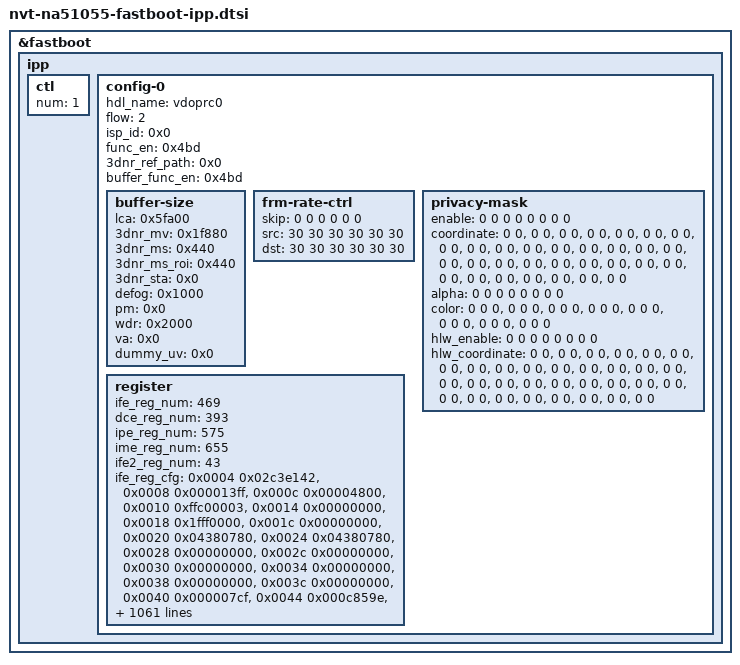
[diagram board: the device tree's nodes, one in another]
&fastboot {
	ipp {
		ctl {
			num = <1>;
		};
		config-0 {
			hdl_name = "vdoprc0";
			flow = <2>;
			isp_id = <0x0>;
			func_en = <0x4bd>;
			3dnr_ref_path = <0x0>;
			buffer_func_en = <0x4bd>;
			buffer-size {
				lca = <0x5fa00>;
				3dnr_mv = <0x1f880>;
				3dnr_ms = <0x440>;
				3dnr_ms_roi = <0x440>;
				3dnr_sta = <0x0>;
				defog = <0x1000>;
				pm = <0x0>;
				wdr = <0x2000>;
				va = <0x0>;
				dummy_uv = <0x0>;
			};
			frm-rate-ctrl {
				skip = <0 0 0 0 0 0>;
				src = <30 30 30 30 30 30>;
				dst = <30 30 30 30 30 30>;
			};
			privacy-mask {
				enable = <0 0 0 0 0 0 0 0>;
				coordinate =
					<0 0>, <0 0>, <0 0>, <0 0>,
					<0 0>, <0 0>, <0 0>, <0 0>,
					<0 0>, <0 0>, <0 0>, <0 0>,
					<0 0>, <0 0>, <0 0>, <0 0>,
					<0 0>, <0 0>, <0 0>, <0 0>,
					<0 0>, <0 0>, <0 0>, <0 0>,
					<0 0>, <0 0>, <0 0>, <0 0>,
					<0 0>, <0 0>, <0 0>, <0 0>;
				alpha = <0 0 0 0 0 0 0 0>;
				color =
					<0 0 0>,
					<0 0 0>,
					<0 0 0>,
					<0 0 0>,
					<0 0 0>,
					<0 0 0>,
					<0 0 0>,
					<0 0 0>;
				hlw_enable = <0 0 0 0 0 0 0 0>;
				hlw_coordinate =
					<0 0>, <0 0>, <0 0>, <0 0>,
					<0 0>, <0 0>, <0 0>, <0 0>,
					<0 0>, <0 0>, <0 0>, <0 0>,
					<0 0>, <0 0>, <0 0>, <0 0>,
					<0 0>, <0 0>, <0 0>, <0 0>,
					<0 0>, <0 0>, <0 0>, <0 0>,
					<0 0>, <0 0>, <0 0>, <0 0>,
					<0 0>, <0 0>, <0 0>, <0 0>;
			};
			register {
			  ife_reg_num = <469>;
			  dce_reg_num = <393>;
			  ipe_reg_num = <575>;
			  ime_reg_num = <655>;
			  ife2_reg_num = <43>;

			  ife_reg_cfg = 
			    <0x0004 0x02c3e142>,
			    <0x0008 0x000013ff>,
			    <0x000c 0x00004800>,
			    <0x0010 0xffc00003>,
			    <0x0014 0x00000000>,
			    <0x0018 0x1fff0000>,
			    <0x001c 0x00000000>,
			    <0x0020 0x04380780>,
			    <0x0024 0x04380780>,
			    <0x0028 0x00000000>,
			    <0x002c 0x00000000>,
			    <0x0030 0x00000000>,
			    <0x0034 0x00000000>,
			    <0x0038 0x00000000>,
			    <0x003c 0x00000000>,
			    <0x0040 0x000007cf>,
			    <0x0044 0x000c859e>,
			    <0x0048 0x00008b8c>,
			    <0x004c 0x00000000>,
			    <0x0050 0x00000000>,
			    <0x0054 0x00800000>,
			    <0x0058 0x00000000>,
			    <0x005c 0x00001000>,
			    <0x0060 0x00000000>,
			    <0x0064 0x00000000>,
			    <0x0068 0x00000000>,
			    <0x006c 0x00000000>,
			    <0x0070 0x000fff08>,
			    <0x0074 0x0110013e>,
			    <0x0078 0x02e50110>,
			    <0x007c 0x00000110>,
			    <0x0080 0x00800080>,
			    <0x0084 0x00800080>,
			    <0x0088 0x00000080>,
			    <0x008c 0x00800080>,
			    <0x0090 0x00800080>,
			    <0x0094 0x00000080>,
			    <0x0098 0x00000000>,
			    <0x009c 0x00000000>,
			    <0x00a0 0x00000000>,
			    <0x00a4 0x00000000>,
			    <0x00a8 0x00000000>,
			    <0x00ac 0x00000000>,
			    <0x00b0 0x00f000f0>,
			    <0x00b4 0x00f000f0>,
			    <0x00b8 0x000000f0>,
			    <0x00bc 0x00000000>,
			    <0x00c0 0x00000000>,
			    <0x00c4 0x00000000>,
			    <0x00c8 0x00000000>,
			    <0x00cc 0x00000000>,
			    <0x00d0 0x00000000>,
			    <0x00d4 0x00000000>,
			    <0x00d8 0x00000000>,
			    <0x00dc 0x00000000>,
			    <0x00e0 0x00000000>,
			    <0x00e4 0x00000000>,
			    <0x00e8 0x00000000>,
			    <0x00ec 0x00000000>,
			    <0x00f0 0x00000000>,
			    <0x00f4 0x00000000>,
			    <0x00f8 0x00000000>,
			    <0x00fc 0x00000000>,
			    <0x0100 0x00080000>,
			    <0x0104 0x00601600>,
			    <0x0108 0x0911171f>,
			    <0x010c 0x00000307>,
			    <0x0110 0x00000000>,
			    <0x0114 0x00010001>,
			    <0x0118 0x00020001>,
			    <0x011c 0x00000000>,
			    <0x0120 0x00000000>,
			    <0x0124 0x00010001>,
			    <0x0128 0x00020001>,
			    <0x012c 0x00000000>,
			    <0x0130 0x00000000>,
			    <0x0134 0x00010001>,
			    <0x0138 0x00020001>,
			    <0x013c 0x00000000>,
			    <0x0140 0x00000000>,
			    <0x0144 0x00010001>,
			    <0x0148 0x00020001>,
			    <0x014c 0x00000000>,
			    <0x0150 0x00000000>,
			    <0x0154 0x00020002>,
			    <0x0158 0x00040002>,
			    <0x015c 0x00000000>,
			    <0x0160 0x00000000>,
			    <0x0164 0x00020002>,
			    <0x0168 0x00040002>,
			    <0x016c 0x00000000>,
			    <0x0170 0x00000000>,
			    <0x0174 0x00020002>,
			    <0x0178 0x00040002>,
			    <0x017c 0x00000000>,
			    <0x0180 0x00000000>,
			    <0x0184 0x00020002>,
			    <0x0188 0x00040002>,
			    <0x018c 0x00000000>,
			    <0x0190 0x002c62c6>,
			    <0x0194 0x0040c40c>,
			    <0x0198 0x006af6af>,
			    <0x019c 0x0093d93d>,
			    <0x01a0 0x00f41f41>,
			    <0x01a4 0x00010000>,
			    <0x01a8 0x00010033>,
			    <0x01ac 0x86543210>,
			    <0x01b0 0x86543210>,
			    <0x01b4 0x00f00001>,
			    <0x01b8 0x008000a0>,
			    <0x01bc 0x000010ff>,
			    <0x01c0 0x00000000>,
			    <0x01c4 0x00010001>,
			    <0x01c8 0x00010001>,
			    <0x01cc 0x00020001>,
			    <0x01d0 0x00020002>,
			    <0x01d4 0x00020002>,
			    <0x01d8 0x00020002>,
			    <0x01dc 0x00030002>,
			    <0x01e0 0x00000003>,
			    <0x01e4 0x00000000>,
			    <0x01e8 0x00010001>,
			    <0x01ec 0x00010001>,
			    <0x01f0 0x00020001>,
			    <0x01f4 0x00020002>,
			    <0x01f8 0x00020002>,
			    <0x01fc 0x00020002>,
			    <0x0200 0x00030002>,
			    <0x0204 0x00000003>,
			    <0x0208 0x00000000>,
			    <0x020c 0x00010001>,
			    <0x0210 0x00010001>,
			    <0x0214 0x00020001>,
			    <0x0218 0x00020002>,
			    <0x021c 0x00020002>,
			    <0x0220 0x00020002>,
			    <0x0224 0x00030002>,
			    <0x0228 0x00000003>,
			    <0x022c 0x00000000>,
			    <0x0230 0x00010001>,
			    <0x0234 0x00010001>,
			    <0x0238 0x00020001>,
			    <0x023c 0x00020002>,
			    <0x0240 0x00020002>,
			    <0x0244 0x00020002>,
			    <0x0248 0x00030002>,
			    <0x024c 0x00000003>,
			    <0x0250 0x00000000>,
			    <0x0254 0x00020002>,
			    <0x0258 0x00020002>,
			    <0x025c 0x00040002>,
			    <0x0260 0x00040004>,
			    <0x0264 0x00040004>,
			    <0x0268 0x00040004>,
			    <0x026c 0x00060004>,
			    <0x0270 0x00000006>,
			    <0x0274 0x00000000>,
			    <0x0278 0x00020002>,
			    <0x027c 0x00020002>,
			    <0x0280 0x00040002>,
			    <0x0284 0x00040004>,
			    <0x0288 0x00040004>,
			    <0x028c 0x00040004>,
			    <0x0290 0x00060004>,
			    <0x0294 0x00000006>,
			    <0x0298 0x00000000>,
			    <0x029c 0x00020002>,
			    <0x02a0 0x00020002>,
			    <0x02a4 0x00040002>,
			    <0x02a8 0x00040004>,
			    <0x02ac 0x00040004>,
			    <0x02b0 0x00040004>,
			    <0x02b4 0x00060004>,
			    <0x02b8 0x00000006>,
			    <0x02bc 0x00000000>,
			    <0x02c0 0x00020002>,
			    <0x02c4 0x00020002>,
			    <0x02c8 0x00040002>,
			    <0x02cc 0x00040004>,
			    <0x02d0 0x00040004>,
			    <0x02d4 0x00040004>,
			    <0x02d8 0x00060004>,
			    <0x02dc 0x00000006>,
			    <0x02e0 0x021c03c0>,
			    <0x02e4 0x021c03c0>,
			    <0x02e8 0x021c03c0>,
			    <0x02ec 0x021c03c0>,
			    <0x02f0 0x003b73b8>,
			    <0x02f4 0xfffc0001>,
			    <0x02f8 0x00000000>,
			    <0x02fc 0x00000000>,
			    <0x0300 0x00000000>,
			    <0x0304 0x00000000>,
			    <0x0308 0x00000000>,
			    <0x030c 0x00000000>,
			    <0x0310 0x00000000>,
			    <0x0314 0x00000000>,
			    <0x0318 0x00000000>,
			    <0x031c 0x00000000>,
			    <0x0320 0x00000000>,
			    <0x0324 0x00000000>,
			    <0x0328 0x00000000>,
			    <0x032c 0x00000000>,
			    <0x0330 0x00000000>,
			    <0x0334 0x00000000>,
			    <0x0338 0x00000000>,
			    <0x033c 0x00000000>,
			    <0x0340 0x00000000>,
			    <0x0344 0x00000000>,
			    <0x0348 0x00000000>,
			    <0x034c 0x00000000>,
			    <0x0350 0x00000000>,
			    <0x0354 0x00000000>,
			    <0x0358 0x00000000>,
			    <0x035c 0x00000000>,
			    <0x0360 0x00000000>,
			    <0x0364 0x00000000>,
			    <0x0368 0x00000000>,
			    <0x036c 0x00000000>,
			    <0x0370 0x00000000>,
			    <0x0374 0x00000000>,
			    <0x0378 0x00000000>,
			    <0x037c 0x00000000>,
			    <0x0380 0x00000000>,
			    <0x0384 0x00000000>,
			    <0x0388 0x09060301>,
			    <0x038c 0x15120f0d>,
			    <0x0390 0x211e1b18>,
			    <0x0394 0x2d2a2724>,
			    <0x0398 0x00000030>,
			    <0x039c 0x1b181000>,
			    <0x03a0 0x1f1e1c1b>,
			    <0x03a4 0x1c1d1e1f>,
			    <0x03a8 0x0c1a1b1c>,
			    <0x03ac 0x00000004>,
			    <0x03b0 0x00000000>,
			    <0x03b4 0x00000000>,
			    <0x03b8 0x00000000>,
			    <0x03bc 0x00000000>,
			    <0x03c0 0x1f1f1f1f>,
			    <0x03c4 0x1e1e1f1f>,
			    <0x03c8 0x14181c1d>,
			    <0x03cc 0x080a0c10>,
			    <0x03d0 0x06060606>,
			    <0x03d4 0x05050505>,
			    <0x03d8 0x04040404>,
			    <0x03dc 0x20010203>,
			    <0x03e0 0x00000000>,
			    <0x03e4 0x00000000>,
			    <0x03e8 0x00000000>,
			    <0x03ec 0x00000000>,
			    <0x03f0 0x00000000>,
			    <0x03f4 0x00000000>,
			    <0x03f8 0x00000000>,
			    <0x03fc 0x00000000>,
			    <0x0400 0x80000000>,
			    <0x0404 0x00000000>,
			    <0x0408 0x00000000>,
			    <0x040c 0x01000000>,
			    <0x0410 0x00000000>,
			    <0x0414 0x00000000>,
			    <0x0418 0x00000000>,
			    <0x041c 0x01000000>,
			    <0x0420 0x00000000>,
			    <0x0424 0x00000000>,
			    <0x0428 0x00000000>,
			    <0x042c 0x00000000>,
			    <0x0430 0x00000000>,
			    <0x0434 0x00000000>,
			    <0x0438 0x00000000>,
			    <0x043c 0x00000000>,
			    <0x0440 0x00000000>,
			    <0x0444 0x00000000>,
			    <0x0448 0x00000000>,
			    <0x044c 0x00000000>,
			    <0x0450 0x00000000>,
			    <0x0454 0x00000000>,
			    <0x0458 0x00000000>,
			    <0x045c 0x00000000>,
			    <0x0460 0x00000000>,
			    <0x0464 0x00000000>,
			    <0x0468 0x00000000>,
			    <0x046c 0x00000000>,
			    <0x0470 0x00000000>,
			    <0x0474 0x00000000>,
			    <0x0478 0x00000000>,
			    <0x047c 0x00000000>,
			    <0x0480 0x00000000>,
			    <0x0484 0x00000000>,
			    <0x0488 0x00000000>,
			    <0x048c 0x00000000>,
			    <0x0490 0x00000000>,
			    <0x0494 0x00000000>,
			    <0x0498 0x00000000>,
			    <0x049c 0x00000000>,
			    <0x04a0 0x00000000>,
			    <0x04a4 0x00000000>,
			    <0x04a8 0x00000000>,
			    <0x04ac 0x00000000>,
			    <0x04b0 0x00000000>,
			    <0x04b4 0x00000000>,
			    <0x04b8 0x00000000>,
			    <0x04bc 0x00000000>,
			    <0x04c0 0x00000000>,
			    <0x04c4 0x00000000>,
			    <0x04c8 0x00000000>,
			    <0x04cc 0x00000000>,
			    <0x04d0 0x00000000>,
			    <0x04d4 0x00000000>,
			    <0x04d8 0x00000000>,
			    <0x04dc 0x00000000>,
			    <0x04e0 0x00000000>,
			    <0x04e4 0x00000000>,
			    <0x04e8 0x00000000>,
			    <0x04ec 0x00000000>,
			    <0x04f0 0x00000000>,
			    <0x04f4 0x00000000>,
			    <0x04f8 0x00000000>,
			    <0x04fc 0x00000000>,
			    <0x0500 0x00000000>,
			    <0x0504 0x00000000>,
			    <0x0508 0x00000000>,
			    <0x050c 0x00000000>,
			    <0x0510 0x00000000>,
			    <0x0514 0x00000000>,
			    <0x0518 0x00000000>,
			    <0x051c 0x00000000>,
			    <0x0520 0x00000000>,
			    <0x0524 0x00000000>,
			    <0x0528 0x00000000>,
			    <0x052c 0x00000000>,
			    <0x0530 0x00000000>,
			    <0x0534 0x00000000>,
			    <0x0538 0x00000000>,
			    <0x053c 0x00000000>,
			    <0x0540 0x00000000>,
			    <0x0544 0x00000000>,
			    <0x0548 0x00000000>,
			    <0x054c 0x00000000>,
			    <0x0550 0x00100110>,
			    <0x0554 0x0ea09ca0>,
			    <0x0558 0x80ea50ca>,
			    <0x055c 0x0c00a800>,
			    <0x0560 0x81007080>,
			    <0x0564 0x00000000>,
			    <0x0568 0x00000000>,
			    <0x056c 0x00000000>,
			    <0x0570 0x00000002>,
			    <0x0574 0x18a41040>,
			    <0x0578 0x10a63a0e>,
			    <0x057c 0x00000886>,
			    <0x0580 0x18a41040>,
			    <0x0584 0x10a63a0e>,
			    <0x0588 0x00000886>,
			    <0x058c 0x00000000>,
			    <0x0590 0xff100fff>,
			    <0x0594 0xff100fff>,
			    <0x0598 0x00000000>,
			    <0x059c 0x00000000>,
			    <0x05a0 0x00400010>,
			    <0x05a4 0x00000100>,
			    <0x05a8 0x00400000>,
			    <0x05ac 0x04000100>,
			    <0x05b0 0x00002222>,
			    <0x05b4 0x00000000>,
			    <0x05b8 0x00000000>,
			    <0x05bc 0x00000000>,
			    <0x05c0 0x00000000>,
			    <0x05c4 0x00000000>,
			    <0x05c8 0x00000000>,
			    <0x05cc 0x00000000>,
			    <0x05d0 0x00000000>,
			    <0x05d4 0x00000000>,
			    <0x05d8 0x00000000>,
			    <0x05dc 0x00000000>,
			    <0x05e0 0x00000000>,
			    <0x05e4 0x00000000>,
			    <0x05e8 0x00000000>,
			    <0x05ec 0x00000000>,
			    <0x05f0 0x00000000>,
			    <0x05f4 0x00000000>,
			    <0x05f8 0x00000000>,
			    <0x05fc 0x00000000>,
			    <0x0600 0x00000004>,
			    <0x0604 0xffffffff>,
			    <0x0608 0x80a0c0e0>,
			    <0x060c 0x10204060>,
			    <0x0610 0x00000000>,
			    <0x0614 0x00000000>,
			    <0x0618 0x06040200>,
			    <0x061c 0x0e0c0a08>,
			    <0x0620 0x16141210>,
			    <0x0624 0x1e1c1a18>,
			    <0x0628 0x26242220>,
			    <0x062c 0x2e2c2a28>,
			    <0x0630 0x36343230>,
			    <0x0634 0x3e3c3a38>,
			    <0x0638 0x55555555>,
			    <0x063c 0x55555555>,
			    <0x0640 0x03430000>,
			    <0x0644 0x060604e9>,
			    <0x0648 0x078b06de>,
			    <0x064c 0x0898081c>,
			    <0x0650 0x09670905>,
			    <0x0654 0x0a0e09be>,
			    <0x0658 0x0a9b0a57>,
			    <0x065c 0x0b140ad9>,
			    <0x0660 0x0b7f0b4b>,
			    <0x0664 0x0bde0bb0>,
			    <0x0668 0x0c340c0a>,
			    <0x066c 0x0c830c5c>,
			    <0x0670 0x0ccb0ca8>,
			    <0x0674 0x0d0d0ced>,
			    <0x0678 0x0d4b0d2d>,
			    <0x067c 0x0d850d69>,
			    <0x0680 0x0dbc0da1>,
			    <0x0684 0x0def0dd6>,
			    <0x0688 0x0e200e08>,
			    <0x068c 0x0e4e0e37>,
			    <0x0690 0x0e790e64>,
			    <0x0694 0x0ea30e8e>,
			    <0x0698 0x0ecb0eb7>,
			    <0x069c 0x0ef10ede>,
			    <0x06a0 0x0f150f03>,
			    <0x06a4 0x0f380f27>,
			    <0x06a8 0x0f5a0f49>,
			    <0x06ac 0x0f7a0f6a>,
			    <0x06b0 0x0f9a0f8a>,
			    <0x06b4 0x0fb80fa9>,
			    <0x06b8 0x0fd50fc7>,
			    <0x06bc 0x0ff20fe4>,
			    <0x06c0 0x00000fff>,
			    <0x06c4 0x00000000>,
			    <0x06c8 0x00000000>,
			    <0x06cc 0x00000000>,
			    <0x06d0 0x00000000>,
			    <0x06d4 0x00000000>,
			    <0x06d8 0x00000000>,
			    <0x06dc 0x00000000>,
			    <0x06e0 0x00000000>,
			    <0x06e4 0x00000000>,
			    <0x06e8 0x00000000>,
			    <0x06ec 0x00000000>,
			    <0x06f0 0x00000000>,
			    <0x06f4 0x00000000>,
			    <0x06f8 0x00000000>,
			    <0x06fc 0x00000000>,
			    <0x0700 0x00000011>,
			    <0x0704 0x0c080400>,
			    <0x0708 0x1c181410>,
			    <0x070c 0x0002aaaa>,
			    <0x0710 0x0002aaaa>,
			    <0x0714 0x00200000>,
			    <0x0718 0x00600040>,
			    <0x071c 0x00a00080>,
			    <0x0720 0x00e000c0>,
			    <0x0724 0x01440100>,
			    <0x0728 0x01e40190>,
			    <0x072c 0x02a40240>,
			    <0x0730 0x03840310>,
			    <0x0734 0x04840400>,
			    <0x0738 0x05a40510>,
			    <0x073c 0x06e40640>,
			    <0x0740 0x08440790>,
			    <0x0744 0x09c40900>,
			    <0x0748 0x0b640a90>,
			    <0x074c 0x0d240c40>,
			    <0x0750 0x0f040e10>,
			    <0x0754 0x00000fff>;

			  dce_reg_cfg = 
			    <0x0004 0x0000c47a>,
			    <0x0008 0x00001fdf>,
			    <0x000c 0x00000000>,
			    <0x0010 0x04380780>,
			    <0x0014 0x00000000>,
			    <0x0018 0x00000010>,
			    <0x001c 0x00400000>,
			    <0x0020 0x00400000>,
			    <0x0024 0x00000780>,
			    <0x0028 0x00400000>,
			    <0x002c 0x00000780>,
			    <0x0030 0x00400000>,
			    <0x0034 0x00000780>,
			    <0x0038 0x00400000>,
			    <0x003c 0x00000780>,
			    <0x0040 0x00000011>,
			    <0x0044 0x00000000>,
			    <0x0048 0x00000000>,
			    <0x004c 0x00000000>,
			    <0x0050 0x00000000>,
			    <0x0054 0x00000000>,
			    <0x0058 0x00000000>,
			    <0x005c 0x00000000>,
			    <0x0060 0x00003003>,
			    <0x0064 0x077f0000>,
			    <0x0068 0x077f0000>,
			    <0x006c 0x0000001e>,
			    <0x0070 0x00000000>,
			    <0x0074 0x00000000>,
			    <0x0078 0x00000000>,
			    <0x007c 0x00000000>,
			    <0x0080 0x00000000>,
			    <0x0084 0x00000000>,
			    <0x0088 0x00000000>,
			    <0x008c 0x00000780>,
			    <0x0090 0x00000000>,
			    <0x0094 0x00000000>,
			    <0x0098 0x00000000>,
			    <0x009c 0x00000000>,
			    <0x00a0 0x00000000>,
			    <0x00a4 0x00400000>,
			    <0x00a8 0x2c0003c0>,
			    <0x00ac 0x000a0028>,
			    <0x00b0 0x80000000>,
			    <0x00b4 0x00000000>,
			    <0x00b8 0xf8888888>,
			    <0x00bc 0x485f7880>,
			    <0x00c0 0x2428303a>,
			    <0x00c4 0x20202020>,
			    <0x00c8 0x20202020>,
			    <0x00cc 0x00a00020>,
			    <0x00d0 0x00014008>,
			    <0x00d4 0x122347ff>,
			    <0x00d8 0x00000111>,
			    <0x00dc 0x00000000>,
			    <0x00e0 0x40081007>,
			    <0x00e4 0x00408003>,
			    <0x00e8 0x00cc00cc>,
			    <0x00ec 0xa80080e6>,
			    <0x00f0 0x00800080>,
			    <0x00f4 0x00010080>,
			    <0x00f8 0x00000100>,
			    <0x00fc 0xffffe0c0>,
			    <0x0100 0x00000000>,
			    <0x0104 0x00000000>,
			    <0x0108 0x00000000>,
			    <0x010c 0x00000000>,
			    <0x0110 0x00000000>,
			    <0x0114 0x00000000>,
			    <0x0118 0x00000000>,
			    <0x011c 0x00000000>,
			    <0x0120 0x0000023f>,
			    <0x0124 0x00400000>,
			    <0x0128 0x00000080>,
			    <0x012c 0x1a734f40>,
			    <0x0130 0x00000100>,
			    <0x0134 0x04080422>,
			    <0x0138 0x0f79cc3b>,
			    <0x013c 0x0fde1c3b>,
			    <0x0140 0x00000000>,
			    <0x0144 0xffffffff>,
			    <0x0148 0xffffffff>,
			    <0x014c 0xffffffff>,
			    <0x0150 0xffffffff>,
			    <0x0154 0x200000ff>,
			    <0x0158 0x00000054>,
			    <0x015c 0x1565193c>,
			    <0x0160 0x160c160c>,
			    <0x0164 0x55050003>,
			    <0x0168 0x00000000>,
			    <0x016c 0x00000000>,
			    <0x0170 0x00000000>,
			    <0x0174 0x00000000>,
			    <0x0178 0x00000000>,
			    <0x017c 0x00000000>,
			    <0x0180 0x00000000>,
			    <0x0184 0x00000000>,
			    <0x0188 0x00000000>,
			    <0x018c 0x00000000>,
			    <0x0190 0x00000000>,
			    <0x0194 0x00000000>,
			    <0x0198 0x00000000>,
			    <0x019c 0x00000000>,
			    <0x01a0 0x00000000>,
			    <0x01a4 0x00000000>,
			    <0x01a8 0x00000000>,
			    <0x01ac 0x00000000>,
			    <0x01b0 0x00000000>,
			    <0x01b4 0x00000000>,
			    <0x01b8 0x00000000>,
			    <0x01bc 0x00000000>,
			    <0x01c0 0x00000000>,
			    <0x01c4 0x00000000>,
			    <0x01c8 0x00000000>,
			    <0x01cc 0x00000000>,
			    <0x01d0 0x00000000>,
			    <0x01d4 0x00000000>,
			    <0x01d8 0x00000000>,
			    <0x01dc 0x00000000>,
			    <0x01e0 0x00000000>,
			    <0x01e4 0x00000000>,
			    <0x01e8 0x00000000>,
			    <0x01ec 0x00000000>,
			    <0x01f0 0x00000000>,
			    <0x01f4 0x00000000>,
			    <0x01f8 0x00000000>,
			    <0x01fc 0x00000000>,
			    <0x0200 0x00000000>,
			    <0x0204 0x00000000>,
			    <0x0208 0x00000000>,
			    <0x020c 0x00000000>,
			    <0x0210 0x00000000>,
			    <0x0214 0x18100800>,
			    <0x0218 0x2624201c>,
			    <0x021c 0x2b2a2928>,
			    <0x0220 0x2f2e2d2c>,
			    <0x0224 0x33323130>,
			    <0x0228 0x37363534>,
			    <0x022c 0x3b3a3938>,
			    <0x0230 0x3f3e3d3c>,
			    <0x0234 0x00005abf>,
			    <0x0238 0x00000000>,
			    <0x023c 0x0ff70fff>,
			    <0x0240 0x0fa10fd8>,
			    <0x0244 0x0ef10f54>,
			    <0x0248 0x0df70e7b>,
			    <0x024c 0x0cd10d68>,
			    <0x0250 0x0b9d0c37>,
			    <0x0254 0x0a700b04>,
			    <0x0258 0x095909e1>,
			    <0x025c 0x085f08d8>,
			    <0x0260 0x078407ee>,
			    <0x0264 0x06c70722>,
			    <0x0268 0x06240673>,
			    <0x026c 0x055c05dc>,
			    <0x0270 0x049004ee>,
			    <0x0274 0x03f9043f>,
			    <0x0278 0x038803bd>,
			    <0x027c 0x0332035b>,
			    <0x0280 0x02f0030f>,
			    <0x0284 0x02a602d4>,
			    <0x0288 0x02620280>,
			    <0x028c 0x02230249>,
			    <0x0290 0x01f30208>,
			    <0x0294 0x01d801e4>,
			    <0x0298 0x01c801cf>,
			    <0x029c 0x01bd01c2>,
			    <0x02a0 0x01b501b9>,
			    <0x02a4 0x01b001b2>,
			    <0x02a8 0x01ac01ae>,
			    <0x02ac 0x01a901aa>,
			    <0x02b0 0x01a601a7>,
			    <0x02b4 0x01a401a5>,
			    <0x02b8 0x01a301a4>,
			    <0x02bc 0x000001a2>,
			    <0x02c0 0x0000808c>,
			    <0x02c4 0xffff0000>,
			    <0x02c8 0x00000000>,
			    <0x02cc 0x00000000>,
			    <0x02d0 0x00000000>,
			    <0x02d4 0x09750679>,
			    <0x02d8 0x17210427>,
			    <0x02dc 0x94f26029>,
			    <0x02e0 0x92cc95d2>,
			    <0x02e4 0xa78ca2b4>,
			    <0x02e8 0xddbeb943>,
			    <0x02ec 0xffffffff>,
			    <0x02f0 0xffffffff>,
			    <0x02f4 0xffffffff>,
			    <0x02f8 0xc2eeffff>,
			    <0x02fc 0x822fa1ed>,
			    <0x0300 0x678a6dc1>,
			    <0x0304 0x72b16c5f>,
			    <0x0308 0x831d7bd1>,
			    <0x030c 0x98db8df1>,
			    <0x0310 0x840792f6>,
			    <0x0314 0x717c7637>,
			    <0x0318 0x5a01696c>,
			    <0x031c 0x4c105384>,
			    <0x0320 0x3ba741d7>,
			    <0x0324 0x34e237cf>,
			    <0x0328 0x30223287>,
			    <0x032c 0x2a4d2d8d>,
			    <0x0330 0x27ae2917>,
			    <0x0334 0x24aa2697>,
			    <0x0338 0x2288234c>,
			    <0x033c 0x1fbd204e>,
			    <0x0340 0x1ee01fdd>,
			    <0x0344 0x1ca51db7>,
			    <0x0348 0x1b071b5c>,
			    <0x034c 0x1a121a4e>,
			    <0x0350 0x1e9f1af9>,
			    <0x0354 0x1f33200d>,
			    <0x0358 0x22a020d2>,
			    <0x035c 0x1dc32041>,
			    <0x0360 0x1a491b55>,
			    <0x0364 0x1b691a98>,
			    <0x0368 0x1c3e1b30>,
			    <0x036c 0x1fc21d73>,
			    <0x0370 0x1fcf2073>,
			    <0x0374 0x1a421e11>,
			    <0x0378 0x1da01a78>,
			    <0x037c 0x1c971d84>,
			    <0x0380 0x11251975>,
			    <0x0384 0x0c430d07>,
			    <0x0388 0x0bad0bac>,
			    <0x038c 0x0b790b06>,
			    <0x0390 0x08660ac7>,
			    <0x0394 0x05860604>,
			    <0x0398 0x05220527>,
			    <0x039c 0x04ba04ad>,
			    <0x03a0 0x03310429>,
			    <0x03a4 0x015e0208>,
			    <0x03a8 0x00f20111>,
			    <0x03ac 0x00d400d1>,
			    <0x03b0 0x00fa00e9>,
			    <0x03b4 0x00a200b3>,
			    <0x03b8 0x008f00b3>,
			    <0x03bc 0x00810078>,
			    <0x03c0 0x004d0060>,
			    <0x03c4 0x004c005d>,
			    <0x03c8 0x00620053>,
			    <0x03cc 0x005f0051>,
			    <0x03d0 0x037f0074>,
			    <0x03d4 0x00000000>,
			    <0x03d8 0x00000000>,
			    <0x03dc 0x00000000>,
			    <0x03e0 0x00000000>,
			    <0x03e4 0x00000000>,
			    <0x03e8 0x00000000>,
			    <0x03ec 0x00000000>,
			    <0x03f0 0x00000000>,
			    <0x03f4 0x00000000>,
			    <0x03f8 0x00000000>,
			    <0x03fc 0x00000000>,
			    <0x0400 0x00000002>,
			    <0x0404 0x021c03c0>,
			    <0x0408 0x00ffffff>,
			    <0x040c 0x12661599>,
			    <0x0410 0x00000400>,
			    <0x0414 0x3fffffff>,
			    <0x0418 0x10001000>,
			    <0x041c 0x00001000>,
			    <0x0420 0x00000000>,
			    <0x0424 0x00000000>,
			    <0x0428 0x00000000>,
			    <0x042c 0x00000000>,
			    <0x0430 0x00000000>,
			    <0x0434 0x00000000>,
			    <0x0438 0x00000000>,
			    <0x043c 0x00000000>,
			    <0x0440 0xffffffff>,
			    <0x0444 0xffffffff>,
			    <0x0448 0xffffffff>,
			    <0x044c 0xffffffff>,
			    <0x0450 0xffffffff>,
			    <0x0454 0xffffffff>,
			    <0x0458 0xffffffff>,
			    <0x045c 0xffffffff>,
			    <0x0460 0xffffffff>,
			    <0x0464 0xffffffff>,
			    <0x0468 0xffffffff>,
			    <0x046c 0xffffffff>,
			    <0x0470 0xffffffff>,
			    <0x0474 0xffffffff>,
			    <0x0478 0xffffffff>,
			    <0x047c 0xffffffff>,
			    <0x0480 0xffffffff>,
			    <0x0484 0xffffffff>,
			    <0x0488 0xffffffff>,
			    <0x048c 0xffffffff>,
			    <0x0490 0xffffffff>,
			    <0x0494 0xffffffff>,
			    <0x0498 0xffffffff>,
			    <0x049c 0xffffffff>,
			    <0x04a0 0xffffffff>,
			    <0x04a4 0xffffffff>,
			    <0x04a8 0xffffffff>,
			    <0x04ac 0xffffffff>,
			    <0x04b0 0xffffffff>,
			    <0x04b4 0xffffffff>,
			    <0x04b8 0xffffffff>,
			    <0x04bc 0xffffffff>,
			    <0x04c0 0x0000ffff>,
			    <0x04c4 0x00000000>,
			    <0x04c8 0x00000000>,
			    <0x04cc 0x00000000>,
			    <0x04d0 0x00000000>,
			    <0x04d4 0x00000000>,
			    <0x04d8 0x00000000>,
			    <0x04dc 0x00000000>,
			    <0x04e0 0x00000000>,
			    <0x04e4 0x00000000>,
			    <0x04e8 0x00000000>,
			    <0x04ec 0x00000000>,
			    <0x04f0 0x00000000>,
			    <0x04f4 0x00000000>,
			    <0x04f8 0x00000000>,
			    <0x04fc 0x00000000>,
			    <0x0500 0x00000000>,
			    <0x0504 0x00000000>,
			    <0x0508 0x00000000>,
			    <0x050c 0x00000000>,
			    <0x0510 0x00000000>,
			    <0x0514 0x00000000>,
			    <0x0518 0x00000000>,
			    <0x051c 0x00000000>,
			    <0x0520 0x00000000>,
			    <0x0524 0x00000000>,
			    <0x0528 0x00000000>,
			    <0x052c 0x00000000>,
			    <0x0530 0x00000000>,
			    <0x0534 0x00000000>,
			    <0x0538 0x00000000>,
			    <0x053c 0x00000000>,
			    <0x0540 0x00000000>,
			    <0x0544 0x00000000>,
			    <0x0548 0x00000000>,
			    <0x054c 0x00000000>,
			    <0x0550 0x00000000>,
			    <0x0554 0x00000000>,
			    <0x0558 0x00000000>,
			    <0x055c 0x00000000>,
			    <0x0560 0x00000000>,
			    <0x0564 0x00000000>,
			    <0x0568 0x00000000>,
			    <0x056c 0x00000000>,
			    <0x0570 0x00000000>,
			    <0x0574 0x00000000>,
			    <0x0578 0x00000000>,
			    <0x057c 0x00000000>,
			    <0x0580 0x00000000>,
			    <0x0584 0x00000000>,
			    <0x0588 0x00000000>,
			    <0x058c 0x00000000>,
			    <0x0590 0x00000000>,
			    <0x0594 0x00000000>,
			    <0x0598 0x00000000>,
			    <0x059c 0x00000000>,
			    <0x05a0 0x00000000>,
			    <0x05a4 0x00000000>,
			    <0x05a8 0x00000000>,
			    <0x05ac 0x00000000>,
			    <0x05b0 0x00000000>,
			    <0x05b4 0x00000000>,
			    <0x05b8 0x00000000>,
			    <0x05bc 0x00000000>,
			    <0x05c0 0x00000000>,
			    <0x05c4 0x00000000>,
			    <0x05c8 0x00000000>,
			    <0x05cc 0x00000000>,
			    <0x05d0 0x00000000>,
			    <0x05d4 0x00000000>,
			    <0x05d8 0x00000000>,
			    <0x05dc 0x00000000>,
			    <0x05e0 0x00000000>,
			    <0x05e4 0x00000000>,
			    <0x05e8 0x00000000>,
			    <0x05ec 0x00000000>,
			    <0x05f0 0x00400000>,
			    <0x05f4 0x00000000>,
			    <0x05f8 0x00000000>,
			    <0x05fc 0x00000000>,
			    <0x0600 0x00000000>,
			    <0x0604 0x00000000>,
			    <0x0608 0x00000000>,
			    <0x060c 0x00000000>,
			    <0x0610 0x20191230>,
			    <0x0614 0x00000000>,
			    <0x0618 0x00000000>,
			    <0x061c 0x00000000>,
			    <0x0620 0x00000000>,
			    <0x0624 0x00000000>;

			  ipe_reg_cfg = 
			    <0x0004 0x00000006>,
			    <0x0008 0x00017edb>,
			    <0x000c 0x00000018>,
			    <0x0010 0x00000000>,
			    <0x0014 0x001e0000>,
			    <0x0018 0x00000438>,
			    <0x001c 0x00000000>,
			    <0x0020 0x00000000>,
			    <0x0024 0x00000000>,
			    <0x0028 0x00000000>,
			    <0x002c 0x1a66e1e4>,
			    <0x0030 0x00000000>,
			    <0x0034 0x00000000>,
			    <0x0038 0x00800000>,
			    <0x003c 0x00800000>,
			    <0x0040 0x00000000>,
			    <0x0044 0x00000000>,
			    <0x0048 0x10000000>,
			    <0x004c 0x00000000>,
			    <0x0050 0x00001ffe>,
			    <0x0054 0x00000000>,
			    <0x0058 0xff040001>,
			    <0x005c 0x00000000>,
			    <0x0060 0x00000000>,
			    <0x0064 0x00000000>,
			    <0x0068 0x00000000>,
			    <0x006c 0x00000000>,
			    <0x0070 0x017c05a3>,
			    <0x0074 0x3e2ec02a>,
			    <0x0078 0x00a013dd>,
			    <0x007c 0x0010100a>,
			    <0x0080 0x00181818>,
			    <0x0084 0x00000333>,
			    <0x0088 0x00010004>,
			    <0x008c 0x00008888>,
			    <0x0090 0x88881000>,
			    <0x0094 0x0006e041>,
			    <0x0098 0xffc6e032>,
			    <0x009c 0x0111016c>,
			    <0x00a0 0x00800801>,
			    <0x00a4 0xffff14b4>,
			    <0x00a8 0x00010000>,
			    <0x00ac 0x01000100>,
			    <0x00b0 0x00600060>,
			    <0x00b4 0x05080000>,
			    <0x00b8 0x40352d20>,
			    <0x00bc 0x40404040>,
			    <0x00c0 0x40404040>,
			    <0x00c4 0x262c3440>,
			    <0x00c8 0x15014000>,
			    <0x00cc 0x40201000>,
			    <0x00d0 0xfff0b480>,
			    <0x00d4 0xd6e2f0ff>,
			    <0x00d8 0xb8bec4cc>,
			    <0x00dc 0x02ccc3ff>,
			    <0x00e0 0x40400001>,
			    <0x00e4 0x00000000>,
			    <0x00e8 0x00004040>,
			    <0x00ec 0x00000000>,
			    <0x00f0 0x41000804>,
			    <0x00f4 0x41000804>,
			    <0x00f8 0x41000804>,
			    <0x00fc 0x00000000>,
			    <0x0100 0x01200001>,
			    <0x0104 0x0fc90018>,
			    <0x0108 0x01bb0f78>,
			    <0x010c 0x0ffd0fcd>,
			    <0x0110 0x01bb0f48>,
			    <0x0114 0x00104080>,
			    <0x0118 0x00000000>,
			    <0x011c 0x00000000>,
			    <0x0120 0x00000000>,
			    <0x0124 0x050a0f14>,
			    <0x0128 0x00000000>,
			    <0x012c 0x00000000>,
			    <0x0130 0x0f0a0500>,
			    <0x0134 0x00000000>,
			    <0x0138 0x10752c4d>,
			    <0x013c 0x120357d5>,
			    <0x0140 0x07af2a80>,
			    <0x0144 0x00000000>,
			    <0x0148 0x282000f4>,
			    <0x014c 0x80808080>,
			    <0x0150 0x80808080>,
			    <0x0154 0x80808080>,
			    <0x0158 0x80808080>,
			    <0x015c 0x80808080>,
			    <0x0160 0x80808080>,
			    <0x0164 0x00000000>,
			    <0x0168 0x00000000>,
			    <0x016c 0x00000000>,
			    <0x0170 0x00000000>,
			    <0x0174 0x00000000>,
			    <0x0178 0x00000000>,
			    <0x017c 0x00000000>,
			    <0x0180 0x00000000>,
			    <0x0184 0x00000000>,
			    <0x0188 0x00000000>,
			    <0x018c 0x00000000>,
			    <0x0190 0x00000000>,
			    <0x0194 0x80808080>,
			    <0x0198 0x80808080>,
			    <0x019c 0x80808080>,
			    <0x01a0 0x80808080>,
			    <0x01a4 0x80808080>,
			    <0x01a8 0x80808080>,
			    <0x01ac 0x00820820>,
			    <0x01b0 0x00820820>,
			    <0x01b4 0x00000000>,
			    <0x01b8 0x0000f03c>,
			    <0x01bc 0x0000008c>,
			    <0x01c0 0x00000000>,
			    <0x01c4 0x00000000>,
			    <0x01c8 0x00ffffff>,
			    <0x01cc 0x008c8080>,
			    <0x01d0 0x80808080>,
			    <0x01d4 0x00000000>,
			    <0x01d8 0x00000000>,
			    <0x01dc 0x08020080>,
			    <0x01e0 0x08020080>,
			    <0x01e4 0x08020080>,
			    <0x01e8 0x08020080>,
			    <0x01ec 0x08020080>,
			    <0x01f0 0x00020080>,
			    <0x01f4 0x00000000>,
			    <0x01f8 0x00000000>,
			    <0x01fc 0x00000000>,
			    <0x0200 0x00000000>,
			    <0x0204 0x00000000>,
			    <0x0208 0x00000000>,
			    <0x020c 0x00000000>,
			    <0x0210 0x00000000>,
			    <0x0214 0x00000000>,
			    <0x0218 0x00000000>,
			    <0x021c 0x00000000>,
			    <0x0220 0x00000000>,
			    <0x0224 0x00000000>,
			    <0x0228 0x00000000>,
			    <0x022c 0x00000000>,
			    <0x0230 0x00000000>,
			    <0x0234 0x00000000>,
			    <0x0238 0x00000000>,
			    <0x023c 0x00000000>,
			    <0x0240 0x00000000>,
			    <0x0244 0x00000000>,
			    <0x0248 0x00000000>,
			    <0x024c 0x00000000>,
			    <0x0250 0x00000000>,
			    <0x0254 0x00000000>,
			    <0x0258 0x00000000>,
			    <0x025c 0x00000000>,
			    <0x0260 0x00000000>,
			    <0x0264 0x00000000>,
			    <0x0268 0x00000000>,
			    <0x026c 0x00000000>,
			    <0x0270 0x00000000>,
			    <0x0274 0x00000000>,
			    <0x0278 0x00000000>,
			    <0x027c 0x00000000>,
			    <0x0280 0x00000000>,
			    <0x0284 0x00000000>,
			    <0x0288 0x00000000>,
			    <0x028c 0x00000000>,
			    <0x0290 0x00000000>,
			    <0x0294 0x00000000>,
			    <0x0298 0x00000000>,
			    <0x029c 0x00000000>,
			    <0x02a0 0x00000000>,
			    <0x02a4 0x00000000>,
			    <0x02a8 0x00000000>,
			    <0x02ac 0x00000000>,
			    <0x02b0 0x00000000>,
			    <0x02b4 0x00000000>,
			    <0x02b8 0x00000000>,
			    <0x02bc 0x00000000>,
			    <0x02c0 0x0000010f>,
			    <0x02c4 0x1a731f40>,
			    <0x02c8 0x00000040>,
			    <0x02cc 0x1a730f40>,
			    <0x02d0 0x00000040>,
			    <0x02d4 0x01e50200>,
			    <0x02d8 0x1ffbb877>,
			    <0x02dc 0x21b80077>,
			    <0x02e0 0x00000000>,
			    <0x02e4 0x00000000>,
			    <0x02e8 0x00000000>,
			    <0x02ec 0x00000000>,
			    <0x02f0 0x00000054>,
			    <0x02f4 0x00000000>,
			    <0x02f8 0x00000000>,
			    <0x02fc 0x00000000>,
			    <0x0300 0x00000000>,
			    <0x0304 0x00000000>,
			    <0x0308 0x00000000>,
			    <0x030c 0x00000000>,
			    <0x0310 0x00000000>,
			    <0x0314 0x00000000>,
			    <0x0318 0x00000000>,
			    <0x031c 0x00000000>,
			    <0x0320 0x00000000>,
			    <0x0324 0x00000000>,
			    <0x0328 0x00000000>,
			    <0x032c 0x00000000>,
			    <0x0330 0x00000000>,
			    <0x0334 0x00000000>,
			    <0x0338 0x00000000>,
			    <0x033c 0x00000818>,
			    <0x0340 0x00000000>,
			    <0x0344 0x00000000>,
			    <0x0348 0x00000000>,
			    <0x034c 0x00000000>,
			    <0x0350 0x00000000>,
			    <0x0354 0x00000000>,
			    <0x0358 0x0ff200ff>,
			    <0x035c 0x000000ff>,
			    <0x0360 0x00000000>,
			    <0x0364 0x00000000>,
			    <0x0368 0x00000000>,
			    <0x036c 0x00000000>,
			    <0x0370 0x00000000>,
			    <0x0374 0x00000000>,
			    <0x0378 0x00000000>,
			    <0x037c 0x00000000>,
			    <0x0380 0x00000000>,
			    <0x0384 0x00800000>,
			    <0x0388 0x54545454>,
			    <0x038c 0x54545454>,
			    <0x0390 0x00000054>,
			    <0x0394 0x00000000>,
			    <0x0398 0x00000000>,
			    <0x039c 0x00000000>,
			    <0x03a0 0x00e00004>,
			    <0x03a4 0x4000d200>,
			    <0x03a8 0x00000000>,
			    <0x03ac 0x00000000>,
			    <0x03b0 0x00000000>,
			    <0x03b4 0x00000000>,
			    <0x03b8 0x00000000>,
			    <0x03bc 0x00000000>,
			    <0x03c0 0x00000000>,
			    <0x03c4 0x00000000>,
			    <0x03c8 0x00000000>,
			    <0x03cc 0x00000000>,
			    <0x03d0 0x00000000>,
			    <0x03d4 0x00000000>,
			    <0x03d8 0x00000000>,
			    <0x03dc 0x00000000>,
			    <0x03e0 0x00000000>,
			    <0x03e4 0x00000000>,
			    <0x03e8 0x00000000>,
			    <0x03ec 0x00000000>,
			    <0x03f0 0x00000000>,
			    <0x03f4 0x00000000>,
			    <0x03f8 0x00000000>,
			    <0x03fc 0x00000000>,
			    <0x0400 0x33acd730>,
			    <0x0404 0x33acd730>,
			    <0x0408 0x33acd730>,
			    <0x040c 0x33acd730>,
			    <0x0410 0x33acd730>,
			    <0x0414 0x33acd730>,
			    <0x0418 0x0c62a48b>,
			    <0x041c 0x34dd2343>,
			    <0x0420 0x34dd2343>,
			    <0x0424 0x34dd2343>,
			    <0x0428 0x34dd2343>,
			    <0x042c 0x34dd2343>,
			    <0x0430 0x34dd2343>,
			    <0x0434 0x111404f1>,
			    <0x0438 0x343cfb3a>,
			    <0x043c 0x343cfb3a>,
			    <0x0440 0x343cfb3a>,
			    <0x0444 0x343cfb3a>,
			    <0x0448 0x343cfb3a>,
			    <0x044c 0x2e8b8edd>,
			    <0x0450 0x0f1384c6>,
			    <0x0454 0x326c871d>,
			    <0x0458 0x326c871d>,
			    <0x045c 0x326c871d>,
			    <0x0460 0x326c871d>,
			    <0x0464 0x326c871d>,
			    <0x0468 0x3fffeff7>,
			    <0x046c 0x2ffbeaf4>,
			    <0x0470 0x2ffbeaf4>,
			    <0x0474 0x2ffbeaf4>,
			    <0x0478 0x2ffbeaf4>,
			    <0x047c 0x2ffbeaf4>,
			    <0x0480 0x2ffbeaf4>,
			    <0x0484 0x0f1384c6>,
			    <0x0488 0x2c5afeb9>,
			    <0x048c 0x2c5afeb9>,
			    <0x0490 0x2c5afeb9>,
			    <0x0494 0x2c5afeb9>,
			    <0x0498 0x2c5afeb9>,
			    <0x049c 0x2c5afeb9>,
			    <0x04a0 0x0f1384c6>,
			    <0x04a4 0x27a9ce6d>,
			    <0x04a8 0x27a9ce6d>,
			    <0x04ac 0x27a9ce6d>,
			    <0x04b0 0x27a9ce6d>,
			    <0x04b4 0x27a9ce6d>,
			    <0x04b8 0x25f96652>,
			    <0x04bc 0x0c62a48b>,
			    <0x04c0 0x22988a1b>,
			    <0x04c4 0x22988a1b>,
			    <0x04c8 0x22988a1b>,
			    <0x04cc 0x22988a1b>,
			    <0x04d0 0x22988a1b>,
			    <0x04d4 0x111404f1>,
			    <0x04d8 0x1fe7d9ed>,
			    <0x04dc 0x1fe7d9ed>,
			    <0x04e0 0x1fe7d9ed>,
			    <0x04e4 0x1fe7d9ed>,
			    <0x04e8 0x1fe7d9ed>,
			    <0x04ec 0x1fe7d9ed>,
			    <0x04f0 0x0f1384c6>,
			    <0x04f4 0x1c76f1b1>,
			    <0x04f8 0x1c76f1b1>,
			    <0x04fc 0x1c76f1b1>,
			    <0x0500 0x1fe7d9ed>,
			    <0x0504 0x1fe7d9ed>,
			    <0x0508 0x1fe7d9ed>,
			    <0x050c 0x0f1384c6>,
			    <0x0510 0x1db745c7>,
			    <0x0514 0x1db745c7>,
			    <0x0518 0x1db745c7>,
			    <0x051c 0x1db745c7>,
			    <0x0520 0x1db745c7>,
			    <0x0524 0x31dc6313>,
			    <0x0528 0x1fe7d9ed>,
			    <0x052c 0x1c76f1b1>,
			    <0x0530 0x1c76f1b1>,
			    <0x0534 0x1c76f1b1>,
			    <0x0538 0x1c76f1b1>,
			    <0x053c 0x1c76f1b1>,
			    <0x0540 0x0f1384c6>,
			    <0x0544 0x1b16999b>,
			    <0x0548 0x1b16999b>,
			    <0x054c 0x1b16999b>,
			    <0x0550 0x1b16999b>,
			    <0x0554 0x1b16999b>,
			    <0x0558 0x1b16999b>,
			    <0x055c 0x1b16999b>,
			    <0x0560 0x1825d568>,
			    <0x0564 0x1825d568>,
			    <0x0568 0x1825d568>,
			    <0x056c 0x1825d568>,
			    <0x0570 0x1825d568>,
			    <0x0574 0x25f96652>,
			    <0x0578 0x21b8520d>,
			    <0x057c 0x14d4f930>,
			    <0x0580 0x14d4f930>,
			    <0x0584 0x14d4f930>,
			    <0x0588 0x14d4f930>,
			    <0x058c 0x0f1384c6>,
			    <0x0590 0x13048511>,
			    <0x0594 0x13048511>,
			    <0x0598 0x13048511>,
			    <0x059c 0x13048511>,
			    <0x05a0 0x13048511>,
			    <0x05a4 0x21b8520d>,
			    <0x05a8 0x0f1384c6>,
			    <0x05ac 0x13048511>,
			    <0x05b0 0x13048511>,
			    <0x05b4 0x13048511>,
			    <0x05b8 0x13048511>,
			    <0x05bc 0x13048511>,
			    <0x05c0 0x22988a1b>,
			    <0x05c4 0x14d4f930>,
			    <0x05c8 0x14d4f930>,
			    <0x05cc 0x14d4f930>,
			    <0x05d0 0x14d4f930>,
			    <0x05d4 0x14d4f930>,
			    <0x05d8 0x14d4f930>,
			    <0x05dc 0x08b1ac49>,
			    <0x05e0 0x14d4f930>,
			    <0x05e4 0x14d4f930>,
			    <0x05e8 0x14d4f930>,
			    <0x05ec 0x14d4f930>,
			    <0x05f0 0x14d4f930>,
			    <0x05f4 0x14d4f930>,
			    <0x05f8 0x111404f1>,
			    <0x05fc 0x16856d4d>,
			    <0x0600 0x1c76f1b1>,
			    <0x0604 0x1c76f1b1>,
			    <0x0608 0x1c76f1b1>,
			    <0x060c 0x1c76f1b1>,
			    <0x0610 0x2aca9aa0>,
			    <0x0614 0x14d4f930>,
			    <0x0618 0x1fe7d9ed>,
			    <0x061c 0x1fe7d9ed>,
			    <0x0620 0x1fe7d9ed>,
			    <0x0624 0x1fe7d9ed>,
			    <0x0628 0x1fe7d9ed>,
			    <0x062c 0x14d4f930>,
			    <0x0630 0x20d819fe>,
			    <0x0634 0x20d819fe>,
			    <0x0638 0x20d819fe>,
			    <0x063c 0x20d819fe>,
			    <0x0640 0x20d819fe>,
			    <0x0644 0x20d819fe>,
			    <0x0648 0x0f1384c6>,
			    <0x064c 0x1ed791db>,
			    <0x0650 0x1ed791db>,
			    <0x0654 0x1ed791db>,
			    <0x0658 0x1ed791db>,
			    <0x065c 0x1ed791db>,
			    <0x0660 0x1825d568>,
			    <0x0664 0x19b63d82>,
			    <0x0668 0x1db745c7>,
			    <0x066c 0x1db745c7>,
			    <0x0670 0x1db745c7>,
			    <0x0674 0x1db745c7>,
			    <0x0678 0x1db745c7>,
			    <0x067c 0x2ffbeaf4>,
			    <0x0680 0x2a0a6a93>,
			    <0x0684 0x1c76f1b1>,
			    <0x0688 0x1c76f1b1>,
			    <0x068c 0x1c76f1b1>,
			    <0x0690 0x1c76f1b1>,
			    <0x0694 0x1c76f1b1>,
			    <0x0698 0x1db745c7>,
			    <0x069c 0x19b63d82>,
			    <0x06a0 0x19b63d82>,
			    <0x06a4 0x19b63d82>,
			    <0x06a8 0x19b63d82>,
			    <0x06ac 0x19b63d82>,
			    <0x06b0 0x19b63d82>,
			    <0x06b4 0x14d4f930>,
			    <0x06b8 0x1825d568>,
			    <0x06bc 0x1825d568>,
			    <0x06c0 0x1825d568>,
			    <0x06c4 0x1825d568>,
			    <0x06c8 0x1825d568>,
			    <0x06cc 0x1ed791db>,
			    <0x06d0 0x2368c229>,
			    <0x06d4 0x1825d568>,
			    <0x06d8 0x1825d568>,
			    <0x06dc 0x1825d568>,
			    <0x06e0 0x1825d568>,
			    <0x06e4 0x1825d568>,
			    <0x06e8 0x0f1384c6>,
			    <0x06ec 0x16856d4d>,
			    <0x06f0 0x16856d4d>,
			    <0x06f4 0x16856d4d>,
			    <0x06f8 0x16856d4d>,
			    <0x06fc 0x16856d4d>,
			    <0x0700 0x00000000>,
			    <0x0704 0x00000000>,
			    <0x0708 0x00000000>,
			    <0x070c 0x00000000>,
			    <0x0710 0x00000000>,
			    <0x0714 0x00000000>,
			    <0x0718 0x00000000>,
			    <0x071c 0x00000000>,
			    <0x0720 0x00000000>,
			    <0x0724 0x00000000>,
			    <0x0728 0x00000000>,
			    <0x072c 0x00000000>,
			    <0x0730 0x00000000>,
			    <0x0734 0x00000000>,
			    <0x0738 0x00000000>,
			    <0x073c 0x00000000>,
			    <0x0740 0x00000000>,
			    <0x0744 0x00000000>,
			    <0x0748 0x00000000>,
			    <0x074c 0x00000000>,
			    <0x0750 0x00000000>,
			    <0x0754 0x00000000>,
			    <0x0758 0x00000000>,
			    <0x075c 0x00000000>,
			    <0x0760 0x00000000>,
			    <0x0764 0x00000000>,
			    <0x0768 0x00000000>,
			    <0x076c 0x00000000>,
			    <0x0770 0x00000000>,
			    <0x0774 0x00000000>,
			    <0x0778 0x00000000>,
			    <0x077c 0x00000000>,
			    <0x0780 0x00000000>,
			    <0x0784 0x00000000>,
			    <0x0788 0x00000000>,
			    <0x078c 0x00000000>,
			    <0x0790 0x00000000>,
			    <0x0794 0x00000000>,
			    <0x0798 0x00000000>,
			    <0x079c 0x00000000>,
			    <0x07a0 0x00000000>,
			    <0x07a4 0x00000000>,
			    <0x07a8 0x00000000>,
			    <0x07ac 0x00000000>,
			    <0x07b0 0x00000000>,
			    <0x07b4 0x00000000>,
			    <0x07b8 0x00000000>,
			    <0x07bc 0x00000000>,
			    <0x07c0 0x00000000>,
			    <0x07c4 0x00000000>,
			    <0x07c8 0x00000000>,
			    <0x07cc 0x00000000>,
			    <0x07d0 0x00000000>,
			    <0x07d4 0x00000000>,
			    <0x07d8 0x00000000>,
			    <0x07dc 0x00000000>,
			    <0x07e0 0x00000000>,
			    <0x07e4 0x00000000>,
			    <0x07e8 0x00000000>,
			    <0x07ec 0x00000000>,
			    <0x07f0 0x00000000>,
			    <0x07f4 0x00000000>,
			    <0x07f8 0x00000000>,
			    <0x07fc 0x00000000>,
			    <0x0800 0x08b12400>,
			    <0x0804 0x1113c4c6>,
			    <0x0808 0x16853530>,
			    <0x080c 0x1b166d82>,
			    <0x0810 0x1ed76dc7>,
			    <0x0814 0x21b835fe>,
			    <0x0818 0x2448da29>,
			    <0x081c 0x26d97e52>,
			    <0x0820 0x293a1e7a>,
			    <0x0824 0x2b9ab2a0>,
			    <0x0828 0x2ddb46c5>,
			    <0x082c 0x2ffbd2e8>,
			    <0x0830 0x31dc4f09>,
			    <0x0834 0x33acc326>,
			    <0x0838 0x356d3743>,
			    <0x083c 0x372da35f>,
			    <0x0840 0x38ce137b>,
			    <0x0844 0x3a6e7b95>,
			    <0x0848 0x3bfedfaf>,
			    <0x084c 0x3d8f43c8>,
			    <0x0850 0x3effa3e0>,
			    <0x0854 0x000ffff7>,
			    <0x0858 0x00000000>,
			    <0x085c 0x00000000>,
			    <0x0860 0x00000000>,
			    <0x0864 0x00000000>,
			    <0x0868 0x00000000>,
			    <0x086c 0x00000000>,
			    <0x0870 0x00000000>,
			    <0x0874 0x00000000>,
			    <0x0878 0x00000000>,
			    <0x087c 0x00000000>,
			    <0x0880 0x00000000>,
			    <0x0884 0x00000000>,
			    <0x0888 0x00000000>,
			    <0x088c 0x00000000>,
			    <0x0890 0x00000000>,
			    <0x0894 0x00000000>,
			    <0x0898 0x00000000>,
			    <0x089c 0x80000000>,
			    <0x08a0 0x00000000>,
			    <0x08a4 0x00000000>,
			    <0x08a8 0x00000000>,
			    <0x08ac 0x00000000>,
			    <0x08b0 0x00000000>,
			    <0x08b4 0x00000000>,
			    <0x08b8 0x00000000>,
			    <0x08bc 0x00000000>,
			    <0x08c0 0x00000000>,
			    <0x08c4 0x00000000>,
			    <0x08c8 0x00000000>,
			    <0x08cc 0x00000000>,
			    <0x08d0 0x00000000>,
			    <0x08d4 0x00000000>,
			    <0x08d8 0x00000000>,
			    <0x08dc 0x00000000>,
			    <0x08e0 0x00000000>,
			    <0x08e4 0x00000000>,
			    <0x08e8 0x00000000>,
			    <0x08ec 0x00000000>,
			    <0x08f0 0x00000000>,
			    <0x08f4 0x00000000>,
			    <0x08f8 0x00000000>,
			    <0x08fc 0x00000000>;

			  ime_reg_cfg = 
			    <0x0004 0x0a00341c>,
			    <0x0008 0x00000000>,
			    <0x000c 0x800001dd>,
			    <0x0010 0x00000000>,
			    <0x0014 0x00000000>,
			    <0x0018 0xa0000040>,
			    <0x001c 0x40000330>,
			    <0x0020 0x04380780>,
			    <0x0024 0x00000020>,
			    <0x0028 0x001e0000>,
			    <0x002c 0x1f040438>,
			    <0x0030 0x00000140>,
			    <0x0034 0x00000140>,
			    <0x0038 0x003c0000>,
			    <0x003c 0x003d2c00>,
			    <0x0040 0x003e5800>,
			    <0x0044 0x00000000>,
			    <0x0048 0x00000000>,
			    <0x004c 0x00000000>,
			    <0x0050 0x00000000>,
			    <0x0054 0x00000000>,
			    <0x0058 0x00000000>,
			    <0x005c 0x00000000>,
			    <0x0060 0x00000012>,
			    <0x0064 0x00000000>,
			    <0x0068 0x00000000>,
			    <0x006c 0x00000000>,
			    <0x0070 0x00000000>,
			    <0x0074 0x00000000>,
			    <0x0078 0x00000000>,
			    <0x007c 0x04380780>,
			    <0x0080 0x00000000>,
			    <0x0084 0x04380780>,
			    <0x0088 0xff00ff00>,
			    <0x008c 0x00000780>,
			    <0x0090 0x00000780>,
			    <0x0094 0x14144000>,
			    <0x0098 0x1433e400>,
			    <0x009c 0x1433e400>,
			    <0x00a0 0x00000000>,
			    <0x00a4 0x00000000>,
			    <0x00a8 0x00000000>,
			    <0x00ac 0x00000000>,
			    <0x00b0 0x0000001e>,
			    <0x00b4 0x0bf78284>,
			    <0x00b8 0x07260044>,
			    <0x00bc 0x06080201>,
			    <0x00c0 0x02a80800>,
			    <0x00c4 0x02a707fc>,
			    <0x00c8 0x02a707f8>,
			    <0x00cc 0x00060200>,
			    <0x00d0 0x00000000>,
			    <0x00d4 0x00000000>,
			    <0x00d8 0x00000000>,
			    <0x00dc 0x00000000>,
			    <0x00e0 0x00000000>,
			    <0x00e4 0x00000000>,
			    <0x00e8 0x00000000>,
			    <0x00ec 0x00000000>,
			    <0x00f0 0x00000000>,
			    <0x00f4 0x00000000>,
			    <0x00f8 0x00000000>,
			    <0x00fc 0x00000000>,
			    <0x0100 0x00000000>,
			    <0x0104 0x00b403c0>,
			    <0x0108 0x00000000>,
			    <0x010c 0x00b403c0>,
			    <0x0110 0xff00ff00>,
			    <0x0114 0x000003c0>,
			    <0x0118 0x000003c0>,
			    <0x011c 0x1a338000>,
			    <0x0120 0x1a362300>,
			    <0x0124 0x00000000>,
			    <0x0128 0x00000000>,
			    <0x012c 0x00000000>,
			    <0x0130 0x0000001e>,
			    <0x0134 0x1af58084>,
			    <0x0138 0x40ab4401>,
			    <0x013c 0x02410245>,
			    <0x0140 0x071c0710>,
			    <0x0144 0x0719070d>,
			    <0x0148 0x0716070a>,
			    <0x014c 0x00020200>,
			    <0x0150 0x00000000>,
			    <0x0154 0x00000000>,
			    <0x0158 0x00000000>,
			    <0x015c 0x00000000>,
			    <0x0160 0x00000000>,
			    <0x0164 0x00000000>,
			    <0x0168 0x00000000>,
			    <0x016c 0x00000000>,
			    <0x0170 0x00000000>,
			    <0x0174 0x00000000>,
			    <0x0178 0x00000000>,
			    <0x017c 0x00000000>,
			    <0x0180 0x00000000>,
			    <0x0184 0x01e00350>,
			    <0x0188 0x00000000>,
			    <0x018c 0x01e00350>,
			    <0x0190 0xff00ff00>,
			    <0x0194 0x00000350>,
			    <0x0198 0x00000350>,
			    <0x019c 0x1a161000>,
			    <0x01a0 0x1a1c4600>,
			    <0x01a4 0x00000000>,
			    <0x01a8 0x00000000>,
			    <0x01ac 0x00000000>,
			    <0x01b0 0x00000112>,
			    <0x01b4 0x00000000>,
			    <0x01b8 0x00000000>,
			    <0x01bc 0x00000000>,
			    <0x01c0 0x00f00140>,
			    <0x01c4 0x00000000>,
			    <0x01c8 0x00f00140>,
			    <0x01cc 0x00000000>,
			    <0x01d0 0x00000050>,
			    <0x01d4 0x00000000>,
			    <0x01d8 0x00499bc0>,
			    <0x01dc 0x00000000>,
			    <0x01e0 0x00000000>,
			    <0x01e4 0x00000000>,
			    <0x01e8 0x00000000>,
			    <0x01ec 0x00000000>,
			    <0x01f0 0x00000000>,
			    <0x01f4 0x00000000>,
			    <0x01f8 0x00000000>,
			    <0x01fc 0x00000000>,
			    <0x0200 0x00000000>,
			    <0x0204 0x00000000>,
			    <0x0208 0x00000000>,
			    <0x020c 0x00000000>,
			    <0x0210 0x00000000>,
			    <0x0214 0x00000000>,
			    <0x0218 0x00000000>,
			    <0x021c 0x00000000>,
			    <0x0220 0x011001e0>,
			    <0x0224 0x404b3fe6>,
			    <0x0228 0x00000140>,
			    <0x022c 0x012b1f00>,
			    <0x0230 0x00000004>,
			    <0x0234 0x00008081>,
			    <0x0238 0x0002000a>,
			    <0x023c 0x000013ff>,
			    <0x0240 0x0002000a>,
			    <0x0244 0x00200022>,
			    <0x0248 0x0200000a>,
			    <0x024c 0x00000000>,
			    <0x0250 0x8000010c>,
			    <0x0254 0xfb46019a>,
			    <0x0258 0x03fc0402>,
			    <0x025c 0x040503ff>,
			    <0x0260 0x040403fe>,
			    <0x0264 0x040303fd>,
			    <0x0268 0x000005a0>,
			    <0x026c 0x1a6b1000>,
			    <0x0270 0x00000505>,
			    <0x0274 0x00000000>,
			    <0x0278 0x00000000>,
			    <0x027c 0x00000000>,
			    <0x0280 0x00008080>,
			    <0x0284 0x16c6b9f0>,
			    <0x0288 0x0a63a12a>,
			    <0x028c 0x00008864>,
			    <0x0290 0x16c6b9f0>,
			    <0x0294 0x0a63a12a>,
			    <0x0298 0x00008864>,
			    <0x029c 0x00000000>,
			    <0x02a0 0x00000000>,
			    <0x02a4 0x00000000>,
			    <0x02a8 0x00000000>,
			    <0x02ac 0x00000000>,
			    <0x02b0 0x00000000>,
			    <0x02b4 0x00000000>,
			    <0x02b8 0x00000000>,
			    <0x02bc 0x00000000>,
			    <0x02c0 0x00000000>,
			    <0x02c4 0x00000000>,
			    <0x02c8 0x00000000>,
			    <0x02cc 0x00000000>,
			    <0x02d0 0x00000000>,
			    <0x02d4 0x00000000>,
			    <0x02d8 0x00000000>,
			    <0x02dc 0x00000000>,
			    <0x02e0 0x00000000>,
			    <0x02e4 0x00000000>,
			    <0x02e8 0x00000000>,
			    <0x02ec 0x00000000>,
			    <0x02f0 0x00000000>,
			    <0x02f4 0x00000000>,
			    <0x02f8 0x00000000>,
			    <0x02fc 0x00000000>,
			    <0x0300 0x00000000>,
			    <0x0304 0x00000000>,
			    <0x0308 0x00000000>,
			    <0x030c 0x00000000>,
			    <0x0310 0x00000000>,
			    <0x0314 0x00000000>,
			    <0x0318 0x00000000>,
			    <0x031c 0x00000000>,
			    <0x0320 0x00000000>,
			    <0x0324 0x00000000>,
			    <0x0328 0x00000000>,
			    <0x032c 0x00000000>,
			    <0x0330 0x00000000>,
			    <0x0334 0x00000000>,
			    <0x0338 0x00000000>,
			    <0x033c 0x00000000>,
			    <0x0340 0x00000000>,
			    <0x0344 0x00000000>,
			    <0x0348 0x00000000>,
			    <0x034c 0x00000000>,
			    <0x0350 0x00000000>,
			    <0x0354 0x00000000>,
			    <0x0358 0x00000000>,
			    <0x035c 0x00000000>,
			    <0x0360 0x00000000>,
			    <0x0364 0x00000000>,
			    <0x0368 0x00000000>,
			    <0x036c 0x00000000>,
			    <0x0370 0x00000000>,
			    <0x0374 0x00000000>,
			    <0x0378 0x00000000>,
			    <0x037c 0x00000000>,
			    <0x0380 0x00000000>,
			    <0x0384 0x00000000>,
			    <0x0388 0x00000000>,
			    <0x038c 0x00000000>,
			    <0x0390 0x00000000>,
			    <0x0394 0x00000000>,
			    <0x0398 0x00000000>,
			    <0x039c 0x00000000>,
			    <0x03a0 0x00000000>,
			    <0x03a4 0x00000000>,
			    <0x03a8 0x00000000>,
			    <0x03ac 0x00000000>,
			    <0x03b0 0x00000000>,
			    <0x03b4 0x00000000>,
			    <0x03b8 0x00000000>,
			    <0x03bc 0x00000000>,
			    <0x03c0 0x00000000>,
			    <0x03c4 0x00000000>,
			    <0x03c8 0x00000000>,
			    <0x03cc 0x00000000>,
			    <0x03d0 0x00000000>,
			    <0x03d4 0x00000000>,
			    <0x03d8 0x00000000>,
			    <0x03dc 0x00000000>,
			    <0x03e0 0x00000000>,
			    <0x03e4 0x00000000>,
			    <0x03e8 0x00000000>,
			    <0x03ec 0x00000000>,
			    <0x03f0 0x00000000>,
			    <0x03f4 0x00000000>,
			    <0x03f8 0x00000000>,
			    <0x03fc 0x00000000>,
			    <0x0400 0x00000000>,
			    <0x0404 0x00000000>,
			    <0x0408 0x00000000>,
			    <0x040c 0x00000000>,
			    <0x0410 0x00000000>,
			    <0x0414 0x00000000>,
			    <0x0418 0x00000000>,
			    <0x041c 0x00000000>,
			    <0x0420 0x00000000>,
			    <0x0424 0x00000000>,
			    <0x0428 0x00000000>,
			    <0x042c 0x00000000>,
			    <0x0430 0x00000000>,
			    <0x0434 0x00000000>,
			    <0x0438 0x00000000>,
			    <0x043c 0x00000000>,
			    <0x0440 0x00000000>,
			    <0x0444 0x00000000>,
			    <0x0448 0x00000000>,
			    <0x044c 0x00000000>,
			    <0x0450 0x00000000>,
			    <0x0454 0x00000000>,
			    <0x0458 0x00000000>,
			    <0x045c 0x00000000>,
			    <0x0460 0x00000000>,
			    <0x0464 0x00000000>,
			    <0x0468 0x00000000>,
			    <0x046c 0x00000000>,
			    <0x0470 0x00000000>,
			    <0x0474 0x00000000>,
			    <0x0478 0x00000000>,
			    <0x047c 0x00000000>,
			    <0x0480 0x00000000>,
			    <0x0484 0x00000000>,
			    <0x0488 0x00000000>,
			    <0x048c 0x00000000>,
			    <0x0490 0x00000000>,
			    <0x0494 0x00000000>,
			    <0x0498 0x00000000>,
			    <0x049c 0x00000000>,
			    <0x04a0 0x00000000>,
			    <0x04a4 0x00000000>,
			    <0x04a8 0x00000000>,
			    <0x04ac 0x00000000>,
			    <0x04b0 0x00000000>,
			    <0x04b4 0x00000000>,
			    <0x04b8 0x00000000>,
			    <0x04bc 0x00000000>,
			    <0x04c0 0x00000000>,
			    <0x04c4 0x00000000>,
			    <0x04c8 0x00000000>,
			    <0x04cc 0x00000000>,
			    <0x04d0 0x00000000>,
			    <0x04d4 0x00000000>,
			    <0x04d8 0x00000000>,
			    <0x04dc 0x00000000>,
			    <0x04e0 0x00000000>,
			    <0x04e4 0x00000000>,
			    <0x04e8 0x00000000>,
			    <0x04ec 0x00000000>,
			    <0x04f0 0x00000000>,
			    <0x04f4 0x00000000>,
			    <0x04f8 0x00000000>,
			    <0x04fc 0x00000000>,
			    <0x0500 0x00000000>,
			    <0x0504 0x00000000>,
			    <0x0508 0x00000000>,
			    <0x050c 0x00000000>,
			    <0x0510 0x00000000>,
			    <0x0514 0x00000000>,
			    <0x0518 0x00000000>,
			    <0x051c 0x00000000>,
			    <0x0520 0x00000000>,
			    <0x0524 0x00000000>,
			    <0x0528 0x00000000>,
			    <0x052c 0x00000000>,
			    <0x0530 0x00000000>,
			    <0x0534 0x00000000>,
			    <0x0538 0x00000000>,
			    <0x053c 0x00000000>,
			    <0x0540 0x00000000>,
			    <0x0544 0x00000000>,
			    <0x0548 0x00000000>,
			    <0x054c 0x00000000>,
			    <0x0550 0x00000000>,
			    <0x0554 0x00000000>,
			    <0x0558 0x00000000>,
			    <0x055c 0x00000000>,
			    <0x0560 0x011001e0>,
			    <0x0564 0x00000001>,
			    <0x0568 0x00000000>,
			    <0x056c 0x00000000>,
			    <0x0570 0x01e00fff>,
			    <0x0574 0x00000000>,
			    <0x0578 0x00000000>,
			    <0x057c 0x00000000>,
			    <0x0580 0x00000000>,
			    <0x0584 0x00000000>,
			    <0x0588 0x00000000>,
			    <0x058c 0x00000000>,
			    <0x0590 0x00000000>,
			    <0x0594 0x00000000>,
			    <0x0598 0x00000000>,
			    <0x059c 0x00000000>,
			    <0x05a0 0x02f00325>,
			    <0x05a4 0x007d00fd>,
			    <0x05a8 0x014f034f>,
			    <0x05ac 0x00000000>,
			    <0x05b0 0x00000000>,
			    <0x05b4 0x02f10780>,
			    <0x05b8 0x02f10780>,
			    <0x05bc 0x02f10780>,
			    <0x05c0 0x00000000>,
			    <0x05c4 0x00000000>,
			    <0x05c8 0x00000000>,
			    <0x05cc 0x00000000>,
			    <0x05d0 0x00000000>,
			    <0x05d4 0x00000000>,
			    <0x05d8 0x00000000>,
			    <0x05dc 0x00000000>,
			    <0x05e0 0x00000000>,
			    <0x05e4 0x00000000>,
			    <0x05e8 0x00000000>,
			    <0x05ec 0x00000000>,
			    <0x05f0 0x00000000>,
			    <0x05f4 0x80000000>,
			    <0x05f8 0x00000000>,
			    <0x05fc 0x00000000>,
			    <0x0600 0x80308f62>,
			    <0x0604 0x00080000>,
			    <0x0608 0x00000000>,
			    <0x060c 0x00000000>,
			    <0x0610 0x00000000>,
			    <0x0614 0x00000000>,
			    <0x0618 0x00000000>,
			    <0x061c 0x02569ce3>,
			    <0x0620 0x0000c0c7>,
			    <0x0624 0x00000000>,
			    <0x0628 0x0000a028>,
			    <0x062c 0x04812048>,
			    <0x0630 0x00018060>,
			    <0x0634 0x1a1a1a1a>,
			    <0x0638 0x1c1b1b1a>,
			    <0x063c 0x000000dc>,
			    <0x0640 0x44444344>,
			    <0x0644 0x001033f3>,
			    <0x0648 0x00003fff>,
			    <0x064c 0x00000000>,
			    <0x0650 0x00000000>,
			    <0x0654 0x00000000>,
			    <0x0658 0x00000000>,
			    <0x065c 0x00000000>,
			    <0x0660 0x09090909>,
			    <0x0664 0x08080808>,
			    <0x0668 0x00230023>,
			    <0x066c 0x00230023>,
			    <0x0670 0x001e001e>,
			    <0x0674 0x001e001e>,
			    <0x0678 0x00190014>,
			    <0x067c 0x00190019>,
			    <0x0680 0x00140014>,
			    <0x0684 0x00140014>,
			    <0x0688 0x00001008>,
			    <0x068c 0x00000000>,
			    <0x0690 0x00000000>,
			    <0x0694 0x00000000>,
			    <0x0698 0x00000000>,
			    <0x069c 0x00000000>,
			    <0x06a0 0x00280028>,
			    <0x06a4 0x00280028>,
			    <0x06a8 0x003c0028>,
			    <0x06ac 0x003c003c>,
			    <0x06b0 0x09090909>,
			    <0x06b4 0x08080808>,
			    <0x06b8 0x00230023>,
			    <0x06bc 0x00230023>,
			    <0x06c0 0x001e001e>,
			    <0x06c4 0x001e001e>,
			    <0x06c8 0x00190014>,
			    <0x06cc 0x00190019>,
			    <0x06d0 0x00140014>,
			    <0x06d4 0x00140014>,
			    <0x06d8 0x00001008>,
			    <0x06dc 0x00000000>,
			    <0x06e0 0x00000000>,
			    <0x06e4 0x00000000>,
			    <0x06e8 0x00000000>,
			    <0x06ec 0x00000000>,
			    <0x06f0 0x00001008>,
			    <0x06f4 0x00000000>,
			    <0x06f8 0x00000000>,
			    <0x06fc 0x00000000>,
			    <0x0700 0x00000000>,
			    <0x0704 0x00000000>,
			    <0x0708 0x00000000>,
			    <0x070c 0x00000000>,
			    <0x0710 0x00001008>,
			    <0x0714 0x00000000>,
			    <0x0718 0x00000000>,
			    <0x071c 0x00000000>,
			    <0x0720 0x00000000>,
			    <0x0724 0x00000000>,
			    <0x0728 0x00000000>,
			    <0x072c 0x00000000>,
			    <0x0730 0x3fff0403>,
			    <0x0734 0x0000e6b4>,
			    <0x0738 0x04000200>,
			    <0x073c 0x00640168>,
			    <0x0740 0x00000000>,
			    <0x0744 0x00000000>,
			    <0x0748 0x00000000>,
			    <0x074c 0x00000000>,
			    <0x0750 0x00000000>,
			    <0x0754 0x00000000>,
			    <0x0758 0x00000000>,
			    <0x075c 0x00000000>,
			    <0x0760 0x00ff0603>,
			    <0x0764 0x018000c0>,
			    <0x0768 0x00000000>,
			    <0x076c 0x00000001>,
			    <0x0770 0x1c181410>,
			    <0x0774 0x00000000>,
			    <0x0778 0x00000000>,
			    <0x077c 0x00000000>,
			    <0x0780 0x00000000>,
			    <0x0784 0x00000000>,
			    <0x0788 0x00000000>,
			    <0x078c 0x00000000>,
			    <0x0790 0x10101010>,
			    <0x0794 0x10101010>,
			    <0x0798 0x00000000>,
			    <0x079c 0x00000000>,
			    <0x07a0 0x00000000>,
			    <0x07a4 0x00000000>,
			    <0x07a8 0x00000000>,
			    <0x07ac 0x00000000>,
			    <0x07b0 0x0a080604>,
			    <0x07b4 0x00000000>,
			    <0x07b8 0x00000000>,
			    <0x07bc 0x00000000>,
			    <0x07c0 0x00004080>,
			    <0x07c4 0x00204000>,
			    <0x07c8 0x00fa00fa>,
			    <0x07cc 0x1c181008>,
			    <0x07d0 0x30201000>,
			    <0x07d4 0x70605040>,
			    <0x07d8 0x1e150b00>,
			    <0x07dc 0x604b3728>,
			    <0x07e0 0x00004080>,
			    <0x07e4 0x00000000>,
			    <0x07e8 0x00000000>,
			    <0x07ec 0x00000000>,
			    <0x07f0 0x00000000>,
			    <0x07f4 0x00000000>,
			    <0x07f8 0x00000000>,
			    <0x07fc 0x00000000>,
			    <0x0800 0x00000780>,
			    <0x0804 0x00000780>,
			    <0x0808 0x13566000>,
			    <0x080c 0x13760400>,
			    <0x0810 0x00000000>,
			    <0x0814 0x00000000>,
			    <0x0818 0x00000000>,
			    <0x081c 0x00000000>,
			    <0x0820 0x00000010>,
			    <0x0824 0x1a730280>,
			    <0x0828 0x00000000>,
			    <0x082c 0x1a730280>,
			    <0x0830 0x00000010>,
			    <0x0834 0x1a7306c0>,
			    <0x0838 0x000001e0>,
			    <0x083c 0x1a710a00>,
			    <0x0840 0x00000000>,
			    <0x0844 0x1a710a00>,
			    <0x0848 0x00000000>,
			    <0x084c 0x00000000>,
			    <0x0850 0x00000000>,
			    <0x0854 0x00000000>,
			    <0x0858 0x00000000>,
			    <0x085c 0x00000000>,
			    <0x0860 0x00000000>,
			    <0x0864 0x00000000>,
			    <0x0868 0x00000000>,
			    <0x086c 0x00000000>,
			    <0x0870 0x00000000>,
			    <0x0874 0x00000000>,
			    <0x0878 0x00000000>,
			    <0x087c 0x00000000>,
			    <0x0880 0x00000000>,
			    <0x0884 0x00000000>,
			    <0x0888 0x00000000>,
			    <0x088c 0x00000000>,
			    <0x0890 0x00000000>,
			    <0x0894 0x00000000>,
			    <0x0898 0x00000000>,
			    <0x089c 0x00000000>,
			    <0x08a0 0x00000000>,
			    <0x08a4 0x00000000>,
			    <0x08a8 0x00000000>,
			    <0x08ac 0x00000000>,
			    <0x08b0 0x00000000>,
			    <0x08b4 0x00000000>,
			    <0x08b8 0x00000000>,
			    <0x08bc 0x00000000>,
			    <0x08c0 0x00000000>,
			    <0x08c4 0x00000000>,
			    <0x08c8 0x00000000>,
			    <0x08cc 0x00000000>,
			    <0x08d0 0x00000000>,
			    <0x08d4 0x00000000>,
			    <0x08d8 0x00000000>,
			    <0x08dc 0x00000000>,
			    <0x08e0 0x00000000>,
			    <0x08e4 0x00000000>,
			    <0x08e8 0x00000000>,
			    <0x08ec 0x00000000>,
			    <0x08f0 0x00000000>,
			    <0x08f4 0x00000000>,
			    <0x08f8 0x00000000>,
			    <0x08fc 0x00000000>,
			    <0x0900 0x00000000>,
			    <0x0904 0x00000000>,
			    <0x0908 0x00000000>,
			    <0x090c 0x00000000>,
			    <0x0910 0x0bb41249>,
			    <0x0914 0x00000748>,
			    <0x0918 0x08e80e39>,
			    <0x091c 0x000005a6>,
			    <0x0920 0x08080ccd>,
			    <0x0924 0x0000051f>,
			    <0x0928 0x07500ba3>,
			    <0x092c 0x000004ae>,
			    <0x0930 0x063509d9>,
			    <0x0934 0x000003f3>,
			    <0x0938 0x05c50925>,
			    <0x093c 0x000003a4>,
			    <0x0940 0x050f0800>,
			    <0x0944 0x00000336>,
			    <0x0948 0x0480071c>,
			    <0x094c 0x000002d9>,
			    <0x0950 0x040e0666>,
			    <0x0954 0x0000028f>,
			    <0x0958 0x03b105d1>,
			    <0x095c 0x00000253>,
			    <0x0960 0x031a04ec>,
			    <0x0964 0x000001f9>,
			    <0x0968 0x02e20492>,
			    <0x096c 0x000001d5>,
			    <0x0970 0x02870400>,
			    <0x0974 0x00000199>,
			    <0x0978 0x0240038e>,
			    <0x097c 0x0000016d>,
			    <0x0980 0x02070333>,
			    <0x0984 0x00000148>,
			    <0x0988 0x01730249>,
			    <0x098c 0x000000ea>,
			    <0x0990 0x00e30124>,
			    <0x0994 0x00ba00cc>,
			    <0x0998 0x0092009d>,
			    <0x099c 0x00720080>,
			    <0x09a0 0x005d0066>,
			    <0x09a4 0x0049004f>,
			    <0x09a8 0x00390040>,
			    <0x09ac 0x00250033>,
			    <0x09b0 0x00000000>,
			    <0x09b4 0x00000000>,
			    <0x09b8 0x00000000>,
			    <0x09bc 0x00000000>,
			    <0x09c0 0x0023001c>,
			    <0x09c4 0x0000002d>,
			    <0x09c8 0x002e0024>,
			    <0x09cc 0x0000003a>,
			    <0x09d0 0x00330028>,
			    <0x09d4 0x00000040>,
			    <0x09d8 0x0038002c>,
			    <0x09dc 0x00000046>,
			    <0x09e0 0x00420034>,
			    <0x09e4 0x00000053>,
			    <0x09e8 0x00470038>,
			    <0x09ec 0x0000005a>,
			    <0x09f0 0x00510040>,
			    <0x09f4 0x00000066>,
			    <0x09f8 0x005b0048>,
			    <0x09fc 0x00000073>,
			    <0x0a00 0x00650050>,
			    <0x0a04 0x00000080>,
			    <0x0a08 0x006f0058>,
			    <0x0a0c 0x0000008d>,
			    <0x0a10 0x00840068>,
			    <0x0a14 0x000000a6>,
			    <0x0a18 0x008e0070>,
			    <0x0a1c 0x000000b3>,
			    <0x0a20 0x00a20080>,
			    <0x0a24 0x000000cd>,
			    <0x0a28 0x00b60090>,
			    <0x0a2c 0x000000e6>,
			    <0x0a30 0x00ca00a0>,
			    <0x0a34 0x00000100>,
			    <0x0a38 0x011b00e0>,
			    <0x0a3c 0x00000166>;

			  ife2_reg_cfg = 
			    <0x0004 0x00030060>,
			    <0x0008 0x80000000>,
			    <0x000c 0x00000000>,
			    <0x0010 0x00000000>,
			    <0x0014 0x011001e0>,
			    <0x0018 0x80000000>,
			    <0x001c 0x000005a0>,
			    <0x0020 0x1a6b1000>,
			    <0x0024 0x00000000>,
			    <0x0028 0x00000000>,
			    <0x002c 0x003c0000>,
			    <0x0030 0x00000280>,
			    <0x0034 0x00141000>,
			    <0x0038 0x00000000>,
			    <0x003c 0x00000000>,
			    <0x0040 0x00000000>,
			    <0x0044 0x100d0b08>,
			    <0x0048 0x00051248>,
			    <0x004c 0x100d0b08>,
			    <0x0050 0x00051248>,
			    <0x0054 0x00090909>,
			    <0x0058 0x00002020>,
			    <0x005c 0x100d0b08>,
			    <0x0060 0x00000016>,
			    <0x0064 0x00111110>,
			    <0x0068 0x100d0b08>,
			    <0x006c 0x00000016>,
			    <0x0070 0x00111110>,
			    <0x0074 0x100d0b08>,
			    <0x0078 0x00000016>,
			    <0x007c 0x00111110>,
			    <0x0080 0x0000837d>,
			    <0x0084 0x00033fa5>,
			    <0x0088 0x00000003>,
			    <0x008c 0x0000837d>,
			    <0x0090 0x00030bf4>,
			    <0x0094 0x00000003>,
			    <0x0098 0x0000362f>,
			    <0x009c 0x00000000>,
			    <0x00a0 0x00000000>,
			    <0x00a4 0x00000000>,
			    <0x00a8 0x00000000>,
			    <0x00ac 0x00000000>;

			};
		};
	};
};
